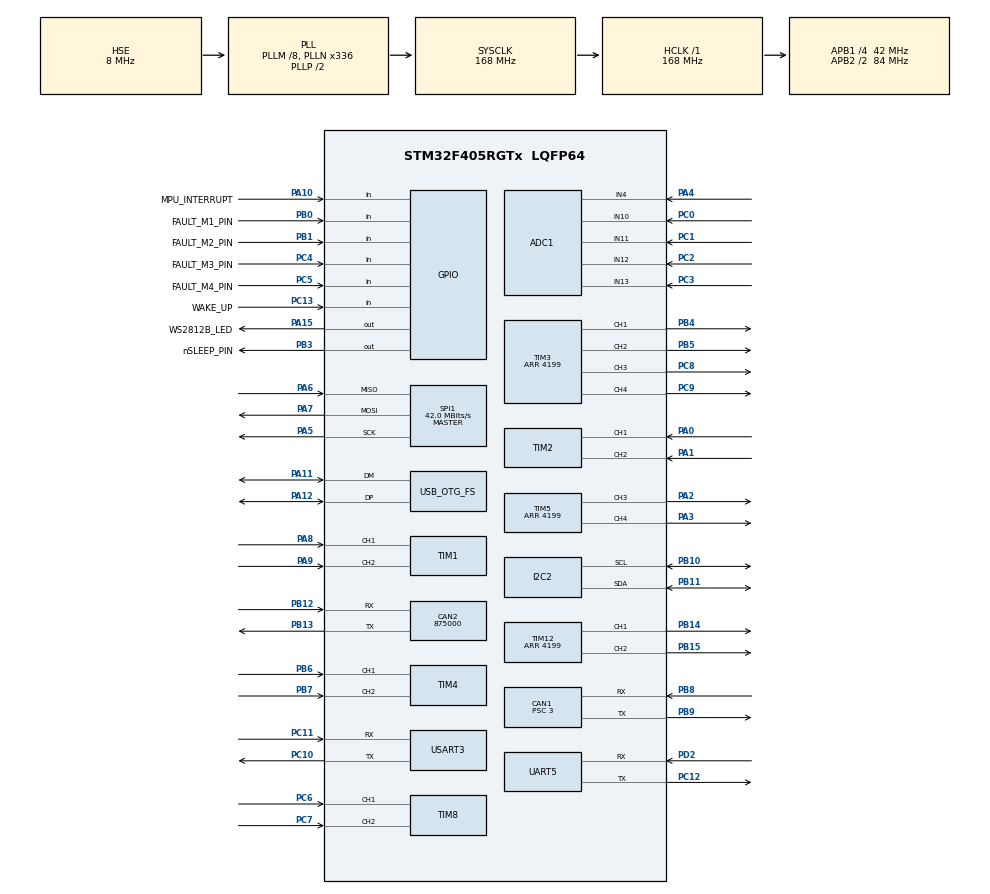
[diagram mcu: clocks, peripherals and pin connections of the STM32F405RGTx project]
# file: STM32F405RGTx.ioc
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ADC1.Channel-1\#ChannelRegularConversion=ADC_CHANNEL_10
ADC1.Channel-2\#ChannelRegularConversion=ADC_CHANNEL_11
ADC1.Channel-3\#ChannelRegularConversion=ADC_CHANNEL_12
ADC1.Channel-4\#ChannelRegularConversion=ADC_CHANNEL_13
ADC1.Channel-5\#ChannelRegularConversion=ADC_CHANNEL_4
ADC1.ContinuousConvMode=ENABLE
ADC1.DMAContinuousRequests=ENABLE
ADC1.NbrOfConversion=5
ADC1.NbrOfConversionFlag=1
ADC1.Rank-1\#ChannelRegularConversion=1
ADC1.Rank-2\#ChannelRegularConversion=2
ADC1.Rank-3\#ChannelRegularConversion=3
ADC1.Rank-4\#ChannelRegularConversion=4
ADC1.Rank-5\#ChannelRegularConversion=5
ADC1.SamplingTime-1\#ChannelRegularConversion=ADC_SAMPLETIME_15CYCLES
ADC1.SamplingTime-2\#ChannelRegularConversion=ADC_SAMPLETIME_15CYCLES
ADC1.SamplingTime-3\#ChannelRegularConversion=ADC_SAMPLETIME_15CYCLES
ADC1.SamplingTime-4\#ChannelRegularConversion=ADC_SAMPLETIME_15CYCLES
ADC1.SamplingTime-5\#ChannelRegularConversion=ADC_SAMPLETIME_15CYCLES
ADC1.ScanConvMode=ENABLE
ADC1.master=1
CAN1.BS1=CAN_BS1_11TQ
CAN1.BS2=CAN_BS2_2TQ
CAN1.CalculateBaudRate=1000000
CAN1.CalculateTimeBit=1000
CAN1.CalculateTimeQuantum=71.42857142857143
CAN1.Prescaler=3
CAN2.CalculateBaudRate=875000
CAN2.CalculateTimeBit=1142
CAN2.CalculateTimeQuantum=380.95238095238096
Dma.ADC1.0.Direction=DMA_PERIPH_TO_MEMORY
Dma.ADC1.0.FIFOMode=DMA_FIFOMODE_DISABLE
Dma.ADC1.0.Instance=DMA2_Stream0
Dma.ADC1.0.MemDataAlignment=DMA_MDATAALIGN_HALFWORD
Dma.ADC1.0.MemInc=DMA_MINC_ENABLE
Dma.ADC1.0.Mode=DMA_CIRCULAR
Dma.ADC1.0.PeriphDataAlignment=DMA_PDATAALIGN_HALFWORD
Dma.ADC1.0.PeriphInc=DMA_PINC_DISABLE
Dma.ADC1.0.Priority=DMA_PRIORITY_MEDIUM
Dma.I2C2_RX.3.Direction=DMA_PERIPH_TO_MEMORY
Dma.I2C2_RX.3.FIFOMode=DMA_FIFOMODE_DISABLE
Dma.I2C2_RX.3.Instance=DMA1_Stream2
Dma.I2C2_RX.3.MemDataAlignment=DMA_MDATAALIGN_BYTE
Dma.I2C2_RX.3.MemInc=DMA_MINC_ENABLE
Dma.I2C2_RX.3.Mode=DMA_NORMAL
Dma.I2C2_RX.3.PeriphDataAlignment=DMA_PDATAALIGN_BYTE
Dma.I2C2_RX.3.PeriphInc=DMA_PINC_DISABLE
Dma.I2C2_RX.3.Priority=DMA_PRIORITY_MEDIUM
Dma.I2C2_TX.4.Direction=DMA_MEMORY_TO_PERIPH
Dma.I2C2_TX.4.FIFOMode=DMA_FIFOMODE_DISABLE
Dma.I2C2_TX.4.Instance=DMA1_Stream7
Dma.I2C2_TX.4.MemDataAlignment=DMA_MDATAALIGN_BYTE
Dma.I2C2_TX.4.MemInc=DMA_MINC_ENABLE
Dma.I2C2_TX.4.Mode=DMA_NORMAL
Dma.I2C2_TX.4.PeriphDataAlignment=DMA_PDATAALIGN_BYTE
Dma.I2C2_TX.4.PeriphInc=DMA_PINC_DISABLE
Dma.I2C2_TX.4.Priority=DMA_PRIORITY_LOW
Dma.Request0=ADC1
Dma.Request1=USART3_TX
Dma.Request2=USART3_RX
Dma.Request3=I2C2_RX
Dma.Request4=I2C2_TX
Dma.Request5=UART5_RX
Dma.UART5_RX.5.Direction=DMA_PERIPH_TO_MEMORY
Dma.UART5_RX.5.FIFOMode=DMA_FIFOMODE_DISABLE
Dma.UART5_RX.5.Instance=DMA1_Stream0
Dma.UART5_RX.5.MemDataAlignment=DMA_MDATAALIGN_BYTE
Dma.UART5_RX.5.MemInc=DMA_MINC_ENABLE
Dma.UART5_RX.5.Mode=DMA_CIRCULAR
Dma.UART5_RX.5.PeriphDataAlignment=DMA_PDATAALIGN_BYTE
Dma.UART5_RX.5.PeriphInc=DMA_PINC_DISABLE
Dma.UART5_RX.5.Priority=DMA_PRIORITY_LOW
Dma.USART3_RX.2.Direction=DMA_PERIPH_TO_MEMORY
Dma.USART3_RX.2.FIFOMode=DMA_FIFOMODE_DISABLE
Dma.USART3_RX.2.Instance=DMA1_Stream1
Dma.USART3_RX.2.MemDataAlignment=DMA_MDATAALIGN_BYTE
Dma.USART3_RX.2.MemInc=DMA_MINC_ENABLE
Dma.USART3_RX.2.Mode=DMA_CIRCULAR
Dma.USART3_RX.2.PeriphDataAlignment=DMA_PDATAALIGN_BYTE
Dma.USART3_RX.2.PeriphInc=DMA_PINC_DISABLE
Dma.USART3_RX.2.Priority=DMA_PRIORITY_MEDIUM
Dma.USART3_TX.1.Direction=DMA_MEMORY_TO_PERIPH
Dma.USART3_TX.1.FIFOMode=DMA_FIFOMODE_DISABLE
Dma.USART3_TX.1.Instance=DMA1_Stream3
Dma.USART3_TX.1.MemDataAlignment=DMA_MDATAALIGN_BYTE
Dma.USART3_TX.1.MemInc=DMA_MINC_ENABLE
Dma.USART3_TX.1.Mode=DMA_NORMAL
Dma.USART3_TX.1.PeriphDataAlignment=DMA_PDATAALIGN_BYTE
Dma.USART3_TX.1.PeriphInc=DMA_PINC_DISABLE
Dma.USART3_TX.1.Priority=DMA_PRIORITY_MEDIUM
FREERTOS.Tasks01=defaultTask,24,128,StartDefaultTask,Default,NULL,Dynamic,NULL,NULL
FREERTOS.configUSE_NEWLIB_REENTRANT=1
IWDG.Prescaler=IWDG_PRESCALER_128
Mcu.Family=STM32F4
Mcu.Name=STM32F405RGTx
Mcu.Package=LQFP64
NVIC.DMA1_Stream0_IRQn=true\:5\:0\:false\:false\:true\:true\:false\:true\:true
NVIC.DMA1_Stream1_IRQn=true\:5\:0\:false\:false\:true\:true\:false\:true\:true
NVIC.DMA1_Stream2_IRQn=true\:5\:0\:false\:false\:true\:true\:false\:true\:true
NVIC.DMA1_Stream3_IRQn=true\:5\:0\:false\:false\:true\:true\:false\:true\:true
NVIC.DMA1_Stream7_IRQn=true\:5\:0\:false\:false\:true\:true\:false\:true\:true
NVIC.DMA2_Stream0_IRQn=true\:5\:0\:false\:false\:true\:true\:false\:true\:true
NVIC.OTG_FS_IRQn=true\:5\:0\:false\:false\:true\:true\:false\:true\:true
NVIC.PriorityGroup=NVIC_PRIORITYGROUP_4
NVIC.TIM1_UP_TIM10_IRQn=true\:5\:0\:false\:false\:true\:true\:true\:true\:true
NVIC.TIM2_IRQn=true\:5\:0\:false\:false\:true\:true\:true\:true\:true
NVIC.TIM4_IRQn=true\:5\:0\:false\:false\:true\:true\:true\:true\:true
NVIC.TIM6_DAC_IRQn=true\:15\:0\:false\:false\:true\:false\:false\:true\:true
NVIC.TIM8_UP_TIM13_IRQn=true\:5\:0\:false\:false\:true\:true\:true\:true\:true
NVIC.TimeBase=TIM6_DAC_IRQn
NVIC.TimeBaseIP=TIM6
NVIC.UART5_IRQn=true\:5\:0\:false\:false\:true\:true\:true\:true\:true
NVIC.USART3_IRQn=true\:5\:0\:false\:false\:true\:true\:true\:true\:true
PA0-WKUP.GPIO_PuPd=GPIO_PULLUP
PA0-WKUP.Signal=S_TIM2_CH1_ETR
PA1.GPIO_PuPd=GPIO_PULLUP
PA1.Signal=S_TIM2_CH2
PA10.GPIO_Label=MPU_INTERRUPT
PA10.Signal=GPIO_Input
PA11.Mode=Device_Only
PA11.Signal=USB_OTG_FS_DM
PA12.Mode=Device_Only
PA12.Signal=USB_OTG_FS_DP
PA13.Mode=Serial_Wire
PA13.Signal=SYS_JTMS-SWDIO
PA14.Mode=Serial_Wire
PA14.Signal=SYS_JTCK-SWCLK
PA15.GPIO_Label=WS2812B_LED
PA15.GPIO_Speed=GPIO_SPEED_FREQ_HIGH
PA15.Signal=GPIO_Output
PA2.Signal=S_TIM5_CH3
PA3.Signal=S_TIM5_CH4
PA4.Signal=ADCx_IN4
PA5.Mode=Full_Duplex_Master
PA5.Signal=SPI1_SCK
PA6.Mode=Full_Duplex_Master
PA6.Signal=SPI1_MISO
PA7.Mode=Full_Duplex_Master
PA7.Signal=SPI1_MOSI
PA8.GPIO_PuPd=GPIO_PULLUP
PA8.Signal=S_TIM1_CH1
PA9.GPIO_PuPd=GPIO_PULLUP
PA9.Signal=S_TIM1_CH2
PB0.GPIO_Label=FAULT_M1_PIN
PB0.GPIO_PuPd=GPIO_PULLUP
PB0.Signal=GPIO_Input
PB1.GPIO_Label=FAULT_M2_PIN
PB1.GPIO_PuPd=GPIO_PULLUP
PB1.Signal=GPIO_Input
PB10.Mode=I2C
PB10.Signal=I2C2_SCL
PB11.Mode=I2C
PB11.Signal=I2C2_SDA
PB12.Mode=CAN_Activate
PB12.Signal=CAN2_RX
PB13.Mode=CAN_Activate
PB13.Signal=CAN2_TX
PB14.Signal=S_TIM12_CH1
PB15.Signal=S_TIM12_CH2
PB3.GPIO_Label=nSLEEP_PIN
PB3.Signal=GPIO_Output
PB4.Signal=S_TIM3_CH1
PB5.Signal=S_TIM3_CH2
PB6.GPIO_PuPd=GPIO_PULLUP
PB6.Signal=S_TIM4_CH1
PB7.GPIO_PuPd=GPIO_PULLUP
PB7.Signal=S_TIM4_CH2
PB8.Mode=CAN_Activate
PB8.Signal=CAN1_RX
PB9.Mode=CAN_Activate
PB9.Signal=CAN1_TX
PC0.Signal=ADCx_IN10
PC1.Signal=ADCx_IN11
PC10.Mode=Asynchronous
PC10.Signal=USART3_TX
PC11.Mode=Asynchronous
PC11.Signal=USART3_RX
PC12.Mode=Asynchronous
PC12.Signal=UART5_TX
PC13-ANTI_TAMP.GPIO_Label=WAKE_UP
PC13-ANTI_TAMP.Signal=GPIO_Input
PC14-OSC32_IN.Mode=LSE-External-Oscillator
PC14-OSC32_IN.Signal=RCC_OSC32_IN
PC15-OSC32_OUT.Mode=LSE-External-Oscillator
PC15-OSC32_OUT.Signal=RCC_OSC32_OUT
PC2.Signal=ADCx_IN12
PC3.Signal=ADCx_IN13
PC4.GPIO_Label=FAULT_M3_PIN
PC4.GPIO_PuPd=GPIO_PULLUP
PC4.Signal=GPIO_Input
PC5.GPIO_Label=FAULT_M4_PIN
PC5.GPIO_PuPd=GPIO_PULLUP
PC5.Signal=GPIO_Input
PC6.GPIO_PuPd=GPIO_PULLUP
PC6.Signal=S_TIM8_CH1
PC7.GPIO_PuPd=GPIO_PULLUP
PC7.Signal=S_TIM8_CH2
PC8.Signal=S_TIM3_CH3
PC9.Signal=S_TIM3_CH4
PD2.Mode=Asynchronous
PD2.Signal=UART5_RX
PH0-OSC_IN.Mode=HSE-External-Oscillator
PH0-OSC_IN.Signal=RCC_OSC_IN
PH1-OSC_OUT.Mode=HSE-External-Oscillator
PH1-OSC_OUT.Signal=RCC_OSC_OUT
ProjectManager.HeapSize=0x2000
ProjectManager.StackSize=0x400
ProjectManager.TargetToolchain=STM32CubeIDE
RCC.48MHZClocksFreq_Value=48000000
RCC.AHBFreq_Value=168000000
RCC.APB1CLKDivider=RCC_HCLK_DIV4
RCC.APB1Freq_Value=42000000
RCC.APB1TimFreq_Value=84000000
RCC.APB2CLKDivider=RCC_HCLK_DIV2
RCC.APB2Freq_Value=84000000
RCC.APB2TimFreq_Value=168000000
RCC.CortexFreq_Value=168000000
RCC.EnbaleCSS=true
RCC.HCLKFreq_Value=168000000
RCC.HSE_VALUE=8000000
RCC.HSI_VALUE=16000000
RCC.PLLM=8
RCC.PLLN=336
RCC.PLLQ=7
RCC.SYSCLKFreq_VALUE=168000000
RCC.SYSCLKSource=RCC_SYSCLKSOURCE_PLLCLK
RCC.VCOOutputFreq_Value=336000000
SH.ADCx_IN10.0=ADC1_IN10,IN10
SH.ADCx_IN11.0=ADC1_IN11,IN11
SH.ADCx_IN12.0=ADC1_IN12,IN12
SH.ADCx_IN13.0=ADC1_IN13,IN13
SH.ADCx_IN4.0=ADC1_IN4,IN4
SH.S_TIM12_CH1.0=TIM12_CH1,PWM Generation1 CH1
SH.S_TIM12_CH2.0=TIM12_CH2,PWM Generation2 CH2
SH.S_TIM1_CH1.0=TIM1_CH1,Encoder_Interface
SH.S_TIM1_CH2.0=TIM1_CH2,Encoder_Interface
SH.S_TIM2_CH1_ETR.0=TIM2_CH1,Encoder_Interface
SH.S_TIM2_CH2.0=TIM2_CH2,Encoder_Interface
SH.S_TIM3_CH1.0=TIM3_CH1,PWM Generation1 CH1
SH.S_TIM3_CH2.0=TIM3_CH2,PWM Generation2 CH2
SH.S_TIM3_CH3.0=TIM3_CH3,PWM Generation3 CH3
SH.S_TIM3_CH4.0=TIM3_CH4,PWM Generation4 CH4
SH.S_TIM4_CH1.0=TIM4_CH1,Encoder_Interface
SH.S_TIM4_CH2.0=TIM4_CH2,Encoder_Interface
SH.S_TIM5_CH3.0=TIM5_CH3,PWM Generation3 CH3
SH.S_TIM5_CH4.0=TIM5_CH4,PWM Generation4 CH4
SH.S_TIM8_CH1.0=TIM8_CH1,Encoder_Interface
SH.S_TIM8_CH2.0=TIM8_CH2,Encoder_Interface
SPI1.CalculateBaudRate=42.0 MBits/s
SPI1.Direction=SPI_DIRECTION_2LINES
SPI1.Mode=SPI_MODE_MASTER
SPI1.VirtualType=VM_MASTER
TIM1.EncoderMode=TIM_ENCODERMODE_TI12
TIM1.IC1Filter=4
TIM1.IC2Filter=4
TIM12.Channel-PWM\ Generation1\ CH1=TIM_CHANNEL_1
TIM12.Channel-PWM\ Generation2\ CH2=TIM_CHANNEL_2
TIM12.Period=4199
TIM2.EncoderMode=TIM_ENCODERMODE_TI12
TIM2.IC1Filter=4
TIM2.IC2Filter=4
TIM3.Channel-PWM\ Generation1\ CH1=TIM_CHANNEL_1
TIM3.Channel-PWM\ Generation2\ CH2=TIM_CHANNEL_2
TIM3.Channel-PWM\ Generation3\ CH3=TIM_CHANNEL_3
TIM3.Channel-PWM\ Generation4\ CH4=TIM_CHANNEL_4
TIM3.Period=4199
TIM4.EncoderMode=TIM_ENCODERMODE_TI12
TIM4.IC1Filter=4
TIM4.IC2Filter=4
TIM5.Channel-PWM\ Generation3\ CH3=TIM_CHANNEL_3
TIM5.Channel-PWM\ Generation4\ CH4=TIM_CHANNEL_4
TIM5.Period=4199
TIM8.EncoderMode=TIM_ENCODERMODE_TI12
TIM8.IC1Filter=4
TIM8.IC2Filter=4
UART5.VirtualMode=Asynchronous
USART3.VirtualMode=VM_ASYNC
USB_DEVICE.CLASS_NAME_FS=CDC
USB_DEVICE.VirtualMode-CDC_FS=Cdc
USB_DEVICE.VirtualModeFS=Cdc_FS
USB_OTG_FS.VirtualMode=Device_Only
VP_FREERTOS_VS_CMSIS_V2.Mode=CMSIS_V2
VP_IWDG_VS_IWDG.Mode=IWDG_Activate
VP_SYS_VS_tim6.Mode=TIM6
VP_USB_DEVICE_VS_USB_DEVICE_CDC_FS.Mode=CDC_FS
board=custom

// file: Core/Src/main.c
/* USER CODE BEGIN Header */
/**
  ******************************************************************************
  * @file           : main.c
  * @brief          : Main program body
  ******************************************************************************
  * @attention
  *
  * Copyright (c) 2025 STMicroelectronics.
  * All rights reserved.
  *
  * This software is licensed under terms that can be found in the LICENSE file
  * in the root directory of this software component.
  * If no LICENSE file comes with this software, it is provided AS-IS.
  *
  ******************************************************************************
  */
/* USER CODE END Header */
#include "main.h"
#include "cmsis_os.h"
#include "adc.h"
#include "can.h"
#include "dma.h"
#include "i2c.h"
#include "iwdg.h"
#include "spi.h"
#include "tim.h"
#include "usart.h"
#include "usb_device.h"
#include "gpio.h"

/* USER CODE BEGIN Includes */
#include "app/app_main.h"
/* USER CODE END Includes */

void SystemClock_Config(void);
void MX_FREERTOS_Init(void);

int main(void)
{

  /* MCU Configuration--------------------------------------------------------*/

  /* Reset of all peripherals, Initializes the Flash interface and the Systick. */
  HAL_Init();

  /* Configure the system clock */
  SystemClock_Config();

  /* Initialize all configured peripherals */
  MX_GPIO_Init();
  MX_DMA_Init();
  MX_ADC1_Init();
  MX_CAN1_Init();
  MX_CAN2_Init();
  MX_I2C2_Init();
  MX_SPI1_Init();
  MX_TIM1_Init();
  MX_TIM2_Init();
  MX_TIM3_Init();
  MX_TIM4_Init();
  MX_TIM5_Init();
  MX_TIM8_Init();
  MX_TIM12_Init();
  MX_UART5_Init();
  MX_USART3_UART_Init();
  // MX_IWDG_Init();
  /* USER CODE BEGIN 2 */
  HAL_Delay(100);
  MX_USB_DEVICE_Init();
  HAL_Delay(1500);
  app_init();
  /* USER CODE END 2 */

  /* Init scheduler */
  osKernelInitialize();  /* Call init function for freertos objects (in cmsis_os2.c) */
  MX_FREERTOS_Init();

  /* Start scheduler */
  osKernelStart();

  /* We should never get here as control is now taken by the scheduler */

  /* Infinite loop */
  while (1)
  {

  }
}

void SystemClock_Config(void)
{
  RCC_OscInitTypeDef RCC_OscInitStruct = {0};
  RCC_ClkInitTypeDef RCC_ClkInitStruct = {0};

  /** Configure the main internal regulator output voltage
  */
  __HAL_RCC_PWR_CLK_ENABLE();
  __HAL_PWR_VOLTAGESCALING_CONFIG(PWR_REGULATOR_VOLTAGE_SCALE1);

  /** Initializes the RCC Oscillators according to the specified parameters
  * in the RCC_OscInitTypeDef structure.
  */
  RCC_OscInitStruct.OscillatorType = RCC_OSCILLATORTYPE_LSI|RCC_OSCILLATORTYPE_HSE;
  RCC_OscInitStruct.HSEState = RCC_HSE_ON;
  RCC_OscInitStruct.LSIState = RCC_LSI_ON;
  RCC_OscInitStruct.PLL.PLLState = RCC_PLL_ON;
  RCC_OscInitStruct.PLL.PLLSource = RCC_PLLSOURCE_HSE;
  RCC_OscInitStruct.PLL.PLLM = 8;
  RCC_OscInitStruct.PLL.PLLN = 336;
  RCC_OscInitStruct.PLL.PLLP = RCC_PLLP_DIV2;
  RCC_OscInitStruct.PLL.PLLQ = 7;
  if (HAL_RCC_OscConfig(&RCC_OscInitStruct) != HAL_OK)
  {
    Error_Handler();
  }

  /** Initializes the CPU, AHB and APB buses clocks
  */
  RCC_ClkInitStruct.ClockType = RCC_CLOCKTYPE_HCLK|RCC_CLOCKTYPE_SYSCLK
                              |RCC_CLOCKTYPE_PCLK1|RCC_CLOCKTYPE_PCLK2;
  RCC_ClkInitStruct.SYSCLKSource = RCC_SYSCLKSOURCE_PLLCLK;
  RCC_ClkInitStruct.AHBCLKDivider = RCC_SYSCLK_DIV1;
  RCC_ClkInitStruct.APB1CLKDivider = RCC_HCLK_DIV4;
  RCC_ClkInitStruct.APB2CLKDivider = RCC_HCLK_DIV2;

  if (HAL_RCC_ClockConfig(&RCC_ClkInitStruct, FLASH_LATENCY_5) != HAL_OK)
  {
    Error_Handler();
  }

  /** Enables the Clock Security System
  */
  HAL_RCC_EnableCSS();
}

void HAL_TIM_PeriodElapsedCallback(TIM_HandleTypeDef *htim)
{
  if (htim->Instance == TIM6)
  {
    HAL_IncTick();
  }
}

void Error_Handler(void)
{
  __disable_irq();
  while (1)
  {
  }
}

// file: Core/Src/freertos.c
/* USER CODE BEGIN Header */
/**
  ******************************************************************************
  * File Name          : freertos.c
  * Description        : Code for freertos applications
  ******************************************************************************
  * @attention
  *
  * Copyright (c) 2025 STMicroelectronics.
  * All rights reserved.
  *
  * This software is licensed under terms that can be found in the LICENSE file
  * in the root directory of this software component.
  * If no LICENSE file comes with this software, it is provided AS-IS.
  *
  ******************************************************************************
  */
/* USER CODE END Header */

#include "FreeRTOS.h"
#include "task.h"
#include "main.h"
#include "cmsis_os.h"

/* USER CODE BEGIN Includes */
#include "app/app_main.h"
#include "app/app_rtos.h"
#include "app/config_storage.h"

/* USER CODE END Includes */

/* USER CODE BEGIN Variables */
osMutexId_t g_usb_tx_mutex = NULL;
/* USER CODE END Variables */
/* Definitions for defaultTask */
osThreadId_t defaultTaskHandle;
const osThreadAttr_t defaultTask_attributes = {
  .name = "defaultTask",
  .stack_size = 128 * 4,
  .priority = (osPriority_t) osPriorityNormal,
};

void StartDefaultTask(void *argument);

extern void MX_USB_DEVICE_Init(void);
void MX_FREERTOS_Init(void); /* (MISRA C 2004 rule 8.1) */

void MX_FREERTOS_Init(void) {

  /* Create the thread(s) */
  /* creation of defaultTask */
  defaultTaskHandle = osThreadNew(StartDefaultTask, NULL, &defaultTask_attributes);

  /* USER CODE BEGIN RTOS_THREADS */
  app_rtos_init();

  /* USER CODE END RTOS_THREADS */

}

void StartDefaultTask(void *argument)
{
  /* init code for USB_DEVICE */
  // MX_USB_DEVICE_Init();
  /* USER CODE BEGIN StartDefaultTask */
  g_usb_tx_mutex = osMutexNew(NULL);
  /* Infinite loop */
  for(;;)
  {
    osDelay(1);
  }
  /* USER CODE END StartDefaultTask */
}
